# nrf9120 register map
Vendor: Nordic Semiconductor; Series: nrf91; File version: 1
CPU: CM33 r0p4, little endian, MPU, FPU, 3 interrupt priority bits, 69 interrupts
Registers are 32-bit, read-write, reset 0x0 unless marked. A register's access mark holds for its fields unless they carry their own. Offsets are from the block's base; [hi:lo] are bit positions; {n}, {i} and the like mark numbered series.

## CC_AES_S — CRYPTOCELL AES engine
Base 0x50841000
{0x400+4i} AES_KEY_0[{i}] (i=0..7) wo — Description collection: AES key value to use. The initial AES_KEY_0[0] register holds the least significant bits [31:0] of the key value.
  [31:0] VALUE — AES key value.
{0x440+4i} AES_IV_0[{i}] (i=0..3) — Description collection: AES Initialization Vector (IV) to use. The initial AES_IV_0[0] register holds the least significant bits [31:0] of the IV.
  [31:0] VALUE — AES non-tunneling or first tunnel stage IV value.
{0x460+4i} AES_CTR[{i}] (i=0..3) — Description collection: AES counter (CTR) to use. The initial AES_CTR[0] register holds the least significant bits [31:0] of the CTR.
  [31:0] VALUE — AES CTR value.
0x470 AES_BUSY ro — Status register for AES engine activity.
  [0] STATUS — AES engine status.
    0=Idle (AES engine is idle); 1=Busy (AES engine is busy)
0x478 AES_SK wo — Writing to this address trigger sampling of the HW key to the AES_KEY_0 register
  [0] AES_SK — Sample HW key to AES_KEY_0 registers.
0x47C AES_CMAC_INIT wo — Writing to this address triggers the AES engine to generate K1 and K2 for AES-CMAC operations.
  [0] ENABLE — Generate K1 and K2 for the AES-CMAC operations.
    1=Enable (Initialize AES-CMAC operations.)
0x4BC AES_REMAINING_BYTES — This register should be set with the amount of remaining bytes until the end of the current AES operation.
  [31:0] VALUE — Remaining bytes util the end of the current AES operation.
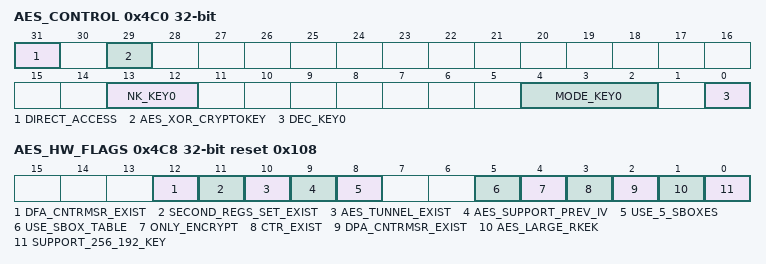
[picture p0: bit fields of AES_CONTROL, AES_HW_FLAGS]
0x4C0 AES_CONTROL — Control the AES engine behavior.
  [31] DIRECT_ACCESS — Using direct access and not the DIN-DOUT DMA interface
    0=Disable (Access using the DIN-DOUT DMA interface); 1=Enable (Access using direct access)
  [29] AES_XOR_CRYPTOKEY — This field determines the value that is written to AES_KEY_0, when AES_SK is kicked.
    0=Disable (The value that is written to AES_KEY_0 is the value of the HW cryptokey as is.); 1=Enable (The value that is written to AES_KEY_0 is the value of the HW cryptokey XOR with the current value of AES_KEY_0.)
  [13:12] NK_KEY0 — Set the AES key length.
    0=128 bits key length
  [4:2] MODE_KEY0 — Set the AES mode.
    0=ECB (Electronic codebook mode); 1=CBC (Cipher block chaining mode); 2=CTR (Counter mode); 3=CBC_MAC (Cipher Block Chaining Message Authentication Code); 7=CMAC (Cipher-based Message Authentication Code)
  [0] DEC_KEY0 — Set AES encrypt or decrypt mode in non-tunneling operations.
    0=Encrypt (Perform AES encryption); 1=Decrypt (Perform AES decryption)
0x4C8 AES_HW_FLAGS ro reset 0x108 — Hardware configuration of the AES engine. Reset value holds the supported features.
  [12] DFA_CNTRMSR_EXIST — If this flag is set, the engine support DFA countermeasures.
  [11] SECOND_REGS_SET_EXIST — If this flag is set, the engine support a second register set for tunneling operations.
  [10] AES_TUNNEL_EXIST — If this flag is set, the engine support tunneling operations.
  [9] AES_SUPPORT_PREV_IV — If this flag is set, the engine contains the PREV_IV register for faster AES XCBC MAC calculation.
  [8] USE_5_SBOXES — If this flag is set, the engine uses 5 SBOX where each AES round takes 4 cycles.
  [5] USE_SBOX_TABLE — If this flag is set, the engine uses SBOX tables.
  [4] ONLY_ENCRYPT — If this flag is set, the engine only support encrypt operations.
  [3] CTR_EXIST — If this flag is set, the engine support AES CTR mode.
  [2] DPA_CNTRMSR_EXIST — If this flag is set, the engine support DPA countermeasures.
  [1] AES_LARGE_RKEK — If this flag is set, the engine support AES_LARGE_RKEK.
  [0] SUPPORT_256_192_KEY — If this flag is set, the engine support 192 bits and 256 bits key size.
0x4D8 AES_CTR_NO_INCREMENT — This register enables the AES CTR no increment mode in which the counter mode is not incremented between two blocks
  [0] ENABLE — This field enables the AES CTR no increment mode in which the counter mode is not incremented between two blocks
    0=Disable (Counter always incremented between blocks); 1=Enable (Do not increment counter between blocks)
0x4F4 AES_SW_RESET wo — Reset the AES engine.
  [0] RESET — Writing any value to this address resets the AES engine. The reset takes 4 CPU clock cycles to complete.
    1=Enable (Reset AES engine.)
0x524 AES_CMAC_SIZE0_KICK wo — Writing to this address triggers the AES engine to perform a CMAC operation with size 0. The CMAC result can be read from the AES_IV_0 register.
  [0] ENABLE — Force AES CMAC operation with size 0.
    0=Disable (Normal AES CMAC operation); 1=Enable (Force CMAC operation with size 0)
